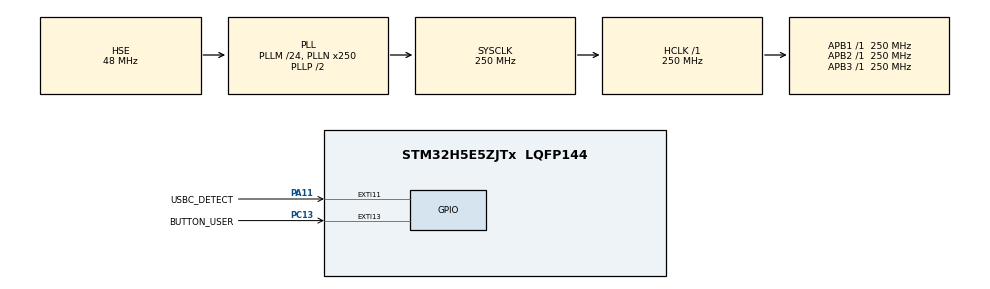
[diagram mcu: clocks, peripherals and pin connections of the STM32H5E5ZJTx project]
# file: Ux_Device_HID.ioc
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CORTEX_M33_NS.userName=CORTEX_M33
Mcu.Family=STM32H5
Mcu.Name=STM32H5E5ZJTx
Mcu.Package=LQFP144
NVIC.EXTI11_IRQn=true\:5\:0\:true\:false\:true\:false\:true\:true\:true
NVIC.EXTI13_IRQn=true\:7\:0\:true\:false\:true\:false\:true\:true\:true
NVIC.OTG_HS_IRQn=true\:6\:0\:true\:false\:true\:false\:true\:true\:true
NVIC.PriorityGroup=NVIC_PRIORITYGROUP_4
NVIC.TIM6_IRQn=true\:15\:0\:false\:false\:true\:false\:false\:true\:true
NVIC.TimeBase=TIM6_IRQn
NVIC.TimeBaseIP=TIM6
OTG_HS_DM.Mode=Internal_Phy_Device
OTG_HS_DM.Signal=USB_OTG_HS_DM
OTG_HS_DP.Mode=Internal_Phy_Device
OTG_HS_DP.Signal=USB_OTG_HS_DP
PA11.GPIO_Label=USBC_DETECT
PA11.GPIO_ModeDefaultEXTI=GPIO_MODE_IT_RISING_FALLING
PA11.Signal=GPXTI11
PC13.GPIO_Label=BUTTON_USER
PC13.GPIO_ModeDefaultEXTI=GPIO_MODE_IT_FALLING
PC13.GPIO_PuPd=GPIO_PULLDOWN
PC13.Signal=GPXTI13
PH0-OSC_IN(PH0).Mode=HSE-External-Oscillator
PH0-OSC_IN(PH0).Signal=RCC_OSC_IN
PH1-OSC_OUT(PH1).Mode=HSE-External-Oscillator
PH1-OSC_OUT(PH1).Signal=RCC_OSC_OUT
ProjectManager.HeapSize=0x200
ProjectManager.StackSize=0x400
ProjectManager.TargetToolchain=EWARM V9.20
RCC.ADCFreq_Value=250000000
RCC.AHBFreq_Value=250000000
RCC.APB1Freq_Value=250000000
RCC.APB1TimFreq_Value=250000000
RCC.APB2Freq_Value=250000000
RCC.APB2TimFreq_Value=250000000
RCC.APB3Freq_Value=250000000
RCC.CSI_VALUE=4000000
RCC.CortexFreq_Value=250000000
RCC.EPOD_VALUE=48000000
RCC.HCLKFreq_Value=250000000
RCC.HSE_VALUE=48000000
RCC.HSI48_VALUE=48000000
RCC.HSI_VALUE=64000000
RCC.LSE_VALUE=32768
RCC.LSIRC_VALUE=32000
RCC.PLL2FRACN=0
RCC.PLL3FRACN=0
RCC.PLLFRACN=0
RCC.PLLM=24
RCC.PLLN=250
RCC.PLLSourceVirtual=RCC_PLL1_SOURCE_HSE
RCC.SYSCLKFreq_VALUE=250000000
RCC.SYSCLKSource=RCC_SYSCLKSOURCE_PLLCLK
RCC.USBFreq_Value=258000000
RCC.USBPHYCLKSource=RCC_OTGHSCLKSOURCE_HSE_DIV2
RCC.VCOOutputFreq_Value=500000000
THREADX.TX_APP_GENERATE_INIT_CODE=false
USBX.BSP.number=1
USBX.Core_System=1
USBX.MAX_POWER_IN_MILLI_AMPER=0
USBX.MAX_POWER_IN_MILLI_AMPER-UX_Device_CoreStack_HS=0
USBX.REG_USBX_DEVICE_CON_CK-UX_Device_CoreStack_HS=0
USBX.USBD_COMPOSITE_USE_IAD-UX_Device_CoreStack_HS=0
USBX.USBD_PRODUCT_STRING-UX_Device_CoreStack_HS=STM32 HID Mouse Device
USBX.USBD_SERIAL_NUMBER-UX_Device_CoreStack_HS=HID001
USBX.USBX_MEM_POOL_VAR_NAME=ux_device_app_byte_pool
USBX.USBX_SYS_SIZE=1024 * 4
USBX.UX_APP_MEM_POOL_SIZE=1024 * 7
USBX.UX_DEVICE_ENABLED_HS=1
USBX.UX_DEVICE_HID_CORE=1
USBX.UX_DEVICE_HID_MOUSE=1
USBX.UX_Device_Controller-UX_Device_Controller_HS=1
USBX.UX_Device_CoreStack=1
USBX.UX_Device_CoreStack-UX_Device_CoreStack_HS=1
USBX.UX_SLAVE_REQUEST_DATA_MAX_LENGTH-UX_Device_CoreStack_HS=64
USBX.UX_enabled_HS=1
USBX0.BSP.STBoard=false
USBX0.BSP.api=Unknown
USBX0.BSP.instance=USB_OTG_HS
USBX0.BSP.ip=USB_OTG_HS
USBX0.BSP.mode=Device_Only
USBX0.BSP.name=UX Device HS
USBX0.BSP.solution=USB_OTG_HS
USB_OTG_HS.VirtualMode=Int_Phy_Device
VP_CORTEX_M33_NS_VS_Hclk.Mode=Hclk_Mode
VP_ICACHE_VS_ICACHE.Mode=DefaultMode
VP_PWR_VS_LPOM.Mode=PowerOptimisation
VP_PWR_VS_SECSignals.Mode=Security/Privilege
VP_SYS_VS_tim6.Mode=TIM6
VP_THREADX_VS_RTOSJjThreadXJjCoreJjDefault.Mode=Core_Default
VP_USBX_Core_System.Mode=Core_System
VP_USBX_UX\ Device\ Controller_HS.Mode=UX_Device_Controller_HS
VP_USBX_UX\ Device\ CoreStack_HS.Mode=UX_Device_CoreStack
VP_USBX_UX\ Device\ HID_CORE_HS.Mode=UX_Device_class_HID_CORE_FS_HS
VP_USBX_UX\ Device\ HID_MOUSE_HS.Mode=UX_Device_class_HID_MOUSE_FS_HS
board=custom

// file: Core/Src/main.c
/* USER CODE BEGIN Header */
/**
  ******************************************************************************
  * @file           : main.c
  * @brief          : Main program body
  ******************************************************************************
  * @attention
  *
  * Copyright (c) 2026 STMicroelectronics.
  * All rights reserved.
  *
  * This software is licensed under terms that can be found in the LICENSE file
  * in the root directory of this software component.
  * If no LICENSE file comes with this software, it is provided AS-IS.
  *
  ******************************************************************************
  */
/* USER CODE END Header */
#include "app_threadx.h"
#include "main.h"

PCD_HandleTypeDef hpcd_USB_OTG_HS;

void SystemClock_Config(void);
static void MX_GPIO_Init(void);
static void MX_ICACHE_Init(void);

int main(void)
{

  /* MCU Configuration--------------------------------------------------------*/

  /* Reset of all peripherals, Initializes the Flash interface and the Systick. */
  HAL_Init();

  /* Configure the system clock */
  SystemClock_Config();

  /* Initialize all configured peripherals */
  MX_GPIO_Init();
  MX_ICACHE_Init();

  MX_ThreadX_Init();

  /* We should never get here as control is now taken by the scheduler */

  /* Infinite loop */
  while (1)
  {

  }
}

void SystemClock_Config(void)
{
  RCC_OscInitTypeDef RCC_OscInitStruct = {0};
  RCC_ClkInitTypeDef RCC_ClkInitStruct = {0};

  /** Configure the main internal regulator output voltage
  */
  __HAL_PWR_VOLTAGESCALING_CONFIG(PWR_REGULATOR_VOLTAGE_SCALE0);

  while(!__HAL_PWR_GET_FLAG(PWR_FLAG_VOSRDY)) {}

  /** Initializes the RCC Oscillators according to the specified parameters
  * in the RCC_OscInitTypeDef structure.
  */
  RCC_OscInitStruct.OscillatorType = RCC_OSCILLATORTYPE_HSE;
  RCC_OscInitStruct.HSEState = RCC_HSE_ON;
  RCC_OscInitStruct.PLL.PLLState = RCC_PLL_ON;
  RCC_OscInitStruct.PLL.PLLSource = RCC_PLL1_SOURCE_HSE;
  RCC_OscInitStruct.PLL.PLLM = 24;
  RCC_OscInitStruct.PLL.PLLN = 250;
  RCC_OscInitStruct.PLL.PLLP = 2;
  RCC_OscInitStruct.PLL.PLLQ = 2;
  RCC_OscInitStruct.PLL.PLLR = 2;
  RCC_OscInitStruct.PLL.PLLRGE = RCC_PLL1_VCIRANGE_1;
  RCC_OscInitStruct.PLL.PLLVCOSEL = RCC_PLL1_VCORANGE_WIDE;
  RCC_OscInitStruct.PLL.PLLFRACN = 0;
  if (HAL_RCC_OscConfig(&RCC_OscInitStruct) != HAL_OK)
  {
    Error_Handler();
  }

  /** Initializes the CPU, AHB and APB buses clocks
  */
  RCC_ClkInitStruct.ClockType = RCC_CLOCKTYPE_HCLK|RCC_CLOCKTYPE_SYSCLK
                              |RCC_CLOCKTYPE_PCLK1|RCC_CLOCKTYPE_PCLK2
                              |RCC_CLOCKTYPE_PCLK3;
  RCC_ClkInitStruct.SYSCLKSource = RCC_SYSCLKSOURCE_PLLCLK;
  RCC_ClkInitStruct.AHBCLKDivider = RCC_SYSCLK_DIV1;
  RCC_ClkInitStruct.APB1CLKDivider = RCC_HCLK_DIV1;
  RCC_ClkInitStruct.APB2CLKDivider = RCC_HCLK_DIV1;
  RCC_ClkInitStruct.APB3CLKDivider = RCC_HCLK_DIV1;

  if (HAL_RCC_ClockConfig(&RCC_ClkInitStruct, FLASH_LATENCY_5) != HAL_OK)
  {
    Error_Handler();
  }

  /** Configure the programming delay
  */
  __HAL_FLASH_SET_PROGRAM_DELAY(FLASH_PROGRAMMING_DELAY_2);
}

static void MX_ICACHE_Init(void)
{

  /** Enable instruction cache (default 2-ways set associative cache)
  */
  if (HAL_ICACHE_Enable() != HAL_OK)
  {
    Error_Handler();
  }

}

void MX_USB_OTG_HS_PCD_Init(void)
{

  /* USER CODE BEGIN USB_OTG_HS_PCD_Init 1 */
  memset(&hpcd_USB_OTG_HS, 0x0, sizeof(PCD_HandleTypeDef));
  /* USER CODE END USB_OTG_HS_PCD_Init 1 */
  hpcd_USB_OTG_HS.Instance = USB_OTG_HS;
  hpcd_USB_OTG_HS.Init.dev_endpoints = 9;
  hpcd_USB_OTG_HS.Init.speed = PCD_SPEED_HIGH;
  hpcd_USB_OTG_HS.Init.dma_enable = DISABLE;
  hpcd_USB_OTG_HS.Init.phy_itface = PCD_HS_PHY_EMBEDDED;
  hpcd_USB_OTG_HS.Init.Sof_enable = DISABLE;
  hpcd_USB_OTG_HS.Init.low_power_enable = DISABLE;
  hpcd_USB_OTG_HS.Init.lpm_enable = DISABLE;
  hpcd_USB_OTG_HS.Init.vbus_sensing_enable = DISABLE;
  if (HAL_PCD_Init(&hpcd_USB_OTG_HS) != HAL_OK)
  {
    Error_Handler();
  }
  /* USER CODE BEGIN USB_OTG_HS_PCD_Init 2 */
  /* Set Rx FIFO */
  HAL_PCDEx_SetRxFiFo(&hpcd_USB_OTG_HS, 0x200);
  /* Set Tx FIFO 0 */
  HAL_PCDEx_SetTxFiFo(&hpcd_USB_OTG_HS, 0, 0x40);
  /* Set Tx FIFO 1 */
  HAL_PCDEx_SetTxFiFo(&hpcd_USB_OTG_HS, 1, 0x100);
  /* USER CODE END USB_OTG_HS_PCD_Init 2 */

}

static void MX_GPIO_Init(void)
{
  GPIO_InitTypeDef GPIO_InitStruct = {0};

  /* GPIO Ports Clock Enable */
  __HAL_RCC_GPIOC_CLK_ENABLE();
  __HAL_RCC_GPIOH_CLK_ENABLE();
  __HAL_RCC_GPIOA_CLK_ENABLE();

  /*Configure GPIO pin : BUTTON_USER_Pin */
  GPIO_InitStruct.Pin = BUTTON_USER_Pin;
  GPIO_InitStruct.Mode = GPIO_MODE_IT_FALLING;
  GPIO_InitStruct.Pull = GPIO_PULLDOWN;
  HAL_GPIO_Init(BUTTON_USER_GPIO_Port, &GPIO_InitStruct);

  /*Configure GPIO pin : USBC_DETECT_Pin */
  GPIO_InitStruct.Pin = USBC_DETECT_Pin;
  GPIO_InitStruct.Mode = GPIO_MODE_IT_RISING_FALLING;
  GPIO_InitStruct.Pull = GPIO_NOPULL;
  HAL_GPIO_Init(USBC_DETECT_GPIO_Port, &GPIO_InitStruct);

  /* EXTI interrupt init*/
  HAL_NVIC_SetPriority(USBC_DETECT_EXTI_IRQn, 5, 0);
  HAL_NVIC_EnableIRQ(USBC_DETECT_EXTI_IRQn);

  HAL_NVIC_SetPriority(BUTTON_USER_EXTI_IRQn, 7, 0);
  HAL_NVIC_EnableIRQ(BUTTON_USER_EXTI_IRQn);

}

void HAL_TIM_PeriodElapsedCallback(TIM_HandleTypeDef *htim)
{
  if (htim->Instance == TIM6)
  {
    HAL_IncTick();
  }
}

void Error_Handler(void)
{
  while (1)
  {
  }
}
